# TM4C1294NCPDT register map
Vendor: Texas Instruments; File version: 2.2.0.295
CPU: CM4 r0p1, little endian, MPU, FPU, 3 interrupt priority bits
Registers are 32-bit, read-write, no defined reset value unless marked. A register's access mark holds for its fields unless they carry their own. Offsets are from the block's base; [hi:lo] are bit positions; <NAME> marks a mode.

## UART0 — UART (UART0)
Base 0x4000C000
Same registers: UART1 0x4000D000, UART2 0x4000E000, UART3 0x4000F000, UART4 0x40010000, UART5 0x40011000, UART6 0x40012000, UART7 0x40013000
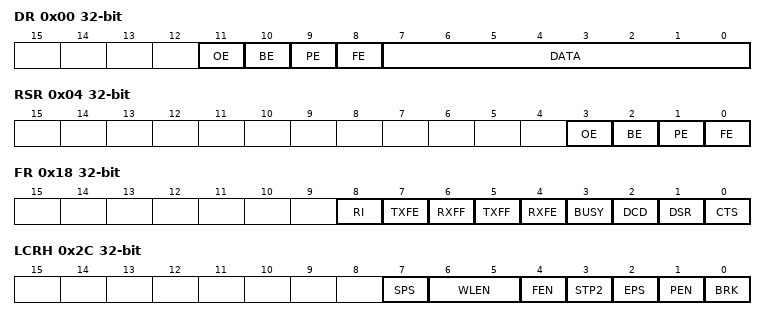
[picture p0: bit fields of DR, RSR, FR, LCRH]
0x00 DR read-modifies
  [11] OE — UART Overrun Error
  [10] BE — UART Break Error
  [9] PE — UART Parity Error
  [8] FE — UART Framing Error
  [7:0] DATA — Data Transmitted or Received
0x04 RSR
  [3] OE — UART Overrun Error
  [2] BE — UART Break Error
  [1] PE — UART Parity Error
  [0] FE — UART Framing Error
0x04 ECR
  [7:0] DATA — Error Clear
0x18 FR
  [8] RI — Ring Indicator
  [7] TXFE — UART Transmit FIFO Empty
  [6] RXFF — UART Receive FIFO Full
  [5] TXFF — UART Transmit FIFO Full
  [4] RXFE — UART Receive FIFO Empty
  [3] BUSY — UART Busy
  [2] DCD — Data Carrier Detect
  [1] DSR — Data Set Ready
  [0] CTS — Clear To Send
0x20 ILPR
  [7:0] ILPDVSR — IrDA Low-Power Divisor
0x24 IBRD
  [15:0] DIVINT — Integer Baud-Rate Divisor
0x28 FBRD
  [5:0] DIVFRAC — Fractional Baud-Rate Divisor
0x2C LCRH
  [7] SPS — UART Stick Parity Select
  [6:5] WLEN — UART Word Length
    0=5 bits (default); 1=6 bits; 2=7 bits; 3=8 bits
  [4] FEN — UART Enable FIFOs
  [3] STP2 — UART Two Stop Bits Select
  [2] EPS — UART Even Parity Select
  [1] PEN — UART Parity Enable
  [0] BRK — UART Send Break
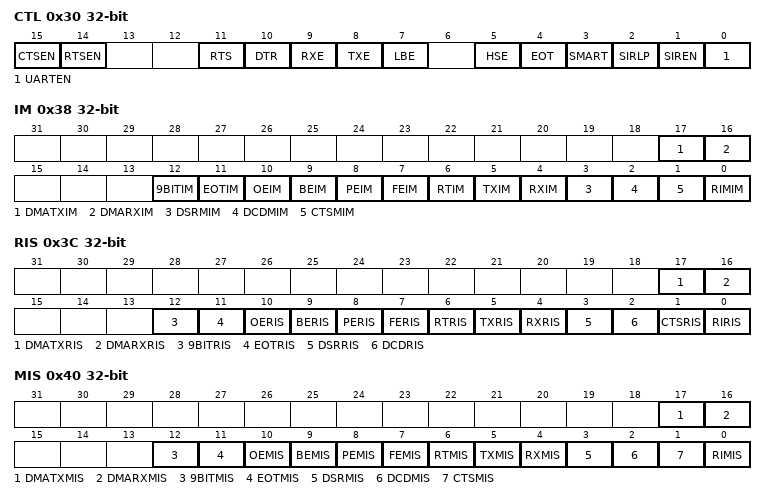
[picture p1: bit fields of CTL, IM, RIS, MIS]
0x30 CTL
  [15] CTSEN — Enable Clear To Send
  [14] RTSEN — Enable Request to Send
  [11] RTS — Request to Send
  [10] DTR — Data Terminal Ready
  [9] RXE — UART Receive Enable
  [8] TXE — UART Transmit Enable
  [7] LBE — UART Loop Back Enable
  [5] HSE — High-Speed Enable
  [4] EOT — End of Transmission
  [3] SMART — ISO 7816 Smart Card Support
  [2] SIRLP — UART SIR Low-Power Mode
  [1] SIREN — UART SIR Enable
  [0] UARTEN — UART Enable
0x34 IFLS
  [5] RX7_8 — RX FIFO >= 7/8 full
  [4] RX4_8 — RX FIFO >= 1/2 full (default)
  [5:3] RX — UART Receive Interrupt FIFO
  [3] RX2_8 — RX FIFO >= 1/4 full
  [4:3] RX6_8 — RX FIFO >= 3/4 full
  [2] TX7_8 — TX FIFO <= 7/8 full
  [1] TX4_8 — TX FIFO <= 1/2 full (default)
  [2:0] TX — UART Transmit Interrupt FIFO
  [0] TX2_8 — TX FIFO <= 1/4 full
  [1:0] TX6_8 — TX FIFO <= 3/4 full
0x38 IM
  [17] DMATXIM — Transmit DMA Interrupt Mask
  [16] DMARXIM — Receive DMA Interrupt Mask
  [12] 9BITIM — 9-Bit Mode Interrupt Mask
  [11] EOTIM — End of Transmission Interrupt
  [10] OEIM — UART Overrun Error Interrupt
  [9] BEIM — UART Break Error Interrupt Mask
  [8] PEIM — UART Parity Error Interrupt Mask
  [7] FEIM — UART Framing Error Interrupt
  [6] RTIM — UART Receive Time-Out Interrupt
  [5] TXIM — UART Transmit Interrupt Mask
  [4] RXIM — UART Receive Interrupt Mask
  [3] DSRMIM — UART Data Set Ready Modem
  [2] DCDMIM — UART Data Carrier Detect Modem
  [1] CTSMIM — UART Clear to Send Modem
  [0] RIMIM — UART Ring Indicator Modem
0x3C RIS
  [17] DMATXRIS — Transmit DMA Raw Interrupt
  [16] DMARXRIS — Receive DMA Raw Interrupt Status
  [12] 9BITRIS — 9-Bit Mode Raw Interrupt Status
  [11] EOTRIS — End of Transmission Raw
  [10] OERIS — UART Overrun Error Raw Interrupt
  [9] BERIS — UART Break Error Raw Interrupt
  [8] PERIS — UART Parity Error Raw Interrupt
  [7] FERIS — UART Framing Error Raw Interrupt
  [6] RTRIS — UART Receive Time-Out Raw
  [5] TXRIS — UART Transmit Raw Interrupt
  [4] RXRIS — UART Receive Raw Interrupt
  [3] DSRRIS — UART Data Set Ready Modem Raw
  [2] DCDRIS — UART Data Carrier Detect Modem
  [1] CTSRIS — UART Clear to Send Modem Raw
  [0] RIRIS — UART Ring Indicator Modem Raw
0x40 MIS
  [17] DMATXMIS — Transmit DMA Masked Interrupt
  [16] DMARXMIS — Receive DMA Masked Interrupt
  [12] 9BITMIS — 9-Bit Mode Masked Interrupt
  [11] EOTMIS — End of Transmission Masked
  [10] OEMIS — UART Overrun Error Masked
  [9] BEMIS — UART Break Error Masked
  [8] PEMIS — UART Parity Error Masked
  [7] FEMIS — UART Framing Error Masked
  [6] RTMIS — UART Receive Time-Out Masked
  [5] TXMIS — UART Transmit Masked Interrupt
  [4] RXMIS — UART Receive Masked Interrupt
  [3] DSRMIS — UART Data Set Ready Modem Masked
  [2] DCDMIS — UART Data Carrier Detect Modem
  [1] CTSMIS — UART Clear to Send Modem Masked
  [0] RIMIS — UART Ring Indicator Modem Masked
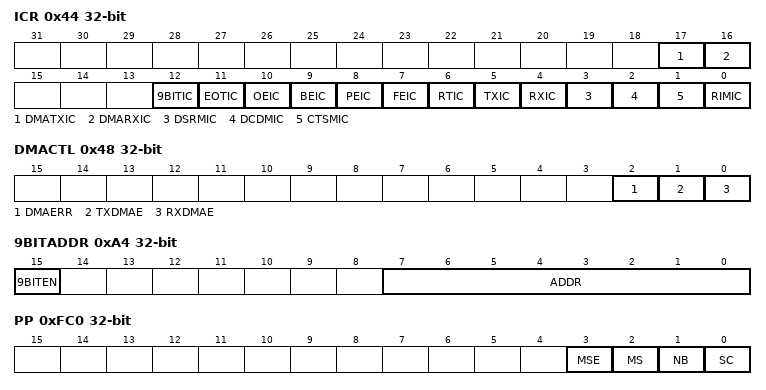
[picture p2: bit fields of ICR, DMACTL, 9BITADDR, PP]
0x44 ICR
  [17] DMATXIC — Transmit DMA Interrupt Clear
  [16] DMARXIC — Receive DMA Interrupt Clear
  [12] 9BITIC — 9-Bit Mode Interrupt Clear
  [11] EOTIC — End of Transmission Interrupt
  [10] OEIC — Overrun Error Interrupt Clear
  [9] BEIC — Break Error Interrupt Clear
  [8] PEIC — Parity Error Interrupt Clear
  [7] FEIC — Framing Error Interrupt Clear
  [6] RTIC — Receive Time-Out Interrupt Clear
  [5] TXIC — Transmit Interrupt Clear
  [4] RXIC — Receive Interrupt Clear
  [3] DSRMIC — UART Data Set Ready Modem
  [2] DCDMIC — UART Data Carrier Detect Modem
  [1] CTSMIC — UART Clear to Send Modem
  [0] RIMIC — UART Ring Indicator Modem
0x48 DMACTL
  [2] DMAERR — DMA on Error
  [1] TXDMAE — Transmit DMA Enable
  [0] RXDMAE — Receive DMA Enable
0xA4 9BITADDR
  [15] 9BITEN — Enable 9-Bit Mode
  [7:0] ADDR — Self Address for 9-Bit Mode
0xA8 9BITAMASK
  [7:0] MASK — Self Address Mask for 9-Bit Mode
0xFC0 PP
  [3] MSE — Modem Support Extended
  [2] MS — Modem Support
  [1] NB — 9-Bit Support
  [0] SC — Smart Card Support
0xFC8 CC
  [3:0] CS — UART Baud Clock Source
    0=SYSCLK (System clock (based on clock); 5=PIOSC
